VERSION ""

NS_ :

BS_:

BU_:

BO_ 0 VECTOR__INDEPENDENT_SIG_MSG: 0 Vector__XXX

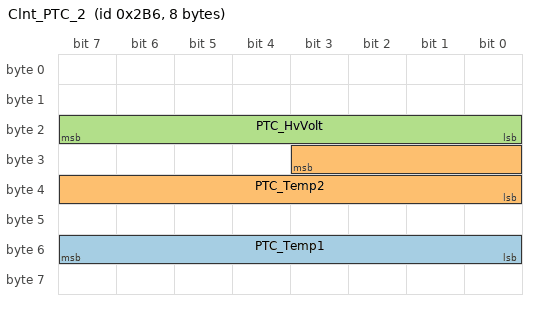
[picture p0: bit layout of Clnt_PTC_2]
BO_ 694 Clnt_PTC_2: 8 Vector__XXX
 SG_ PTC_Temp1 : 55|8@0+ (0.25,0) [0|1] "C" Vector__XXX
 SG_ PTC_Temp2 : 27|12@0+ (0.0625,0) [0|255.9375] "C" Vector__XXX
 SG_ PTC_HvVolt : 23|8@0+ (2,100) [0|1] "V" Vector__XXX

BO_ 693 Clnt_PTC_1: 8 Vector__XXX
 SG_ PTC_HvCur : 39|8@0+ (0.75,0) [0|1] "A" Vector__XXX
 SG_ PTC_HvPow : 23|8@0+ (1,0) [0|1] "" Vector__XXX

CM_ SG_ 693 PTC_HvPow "?";
